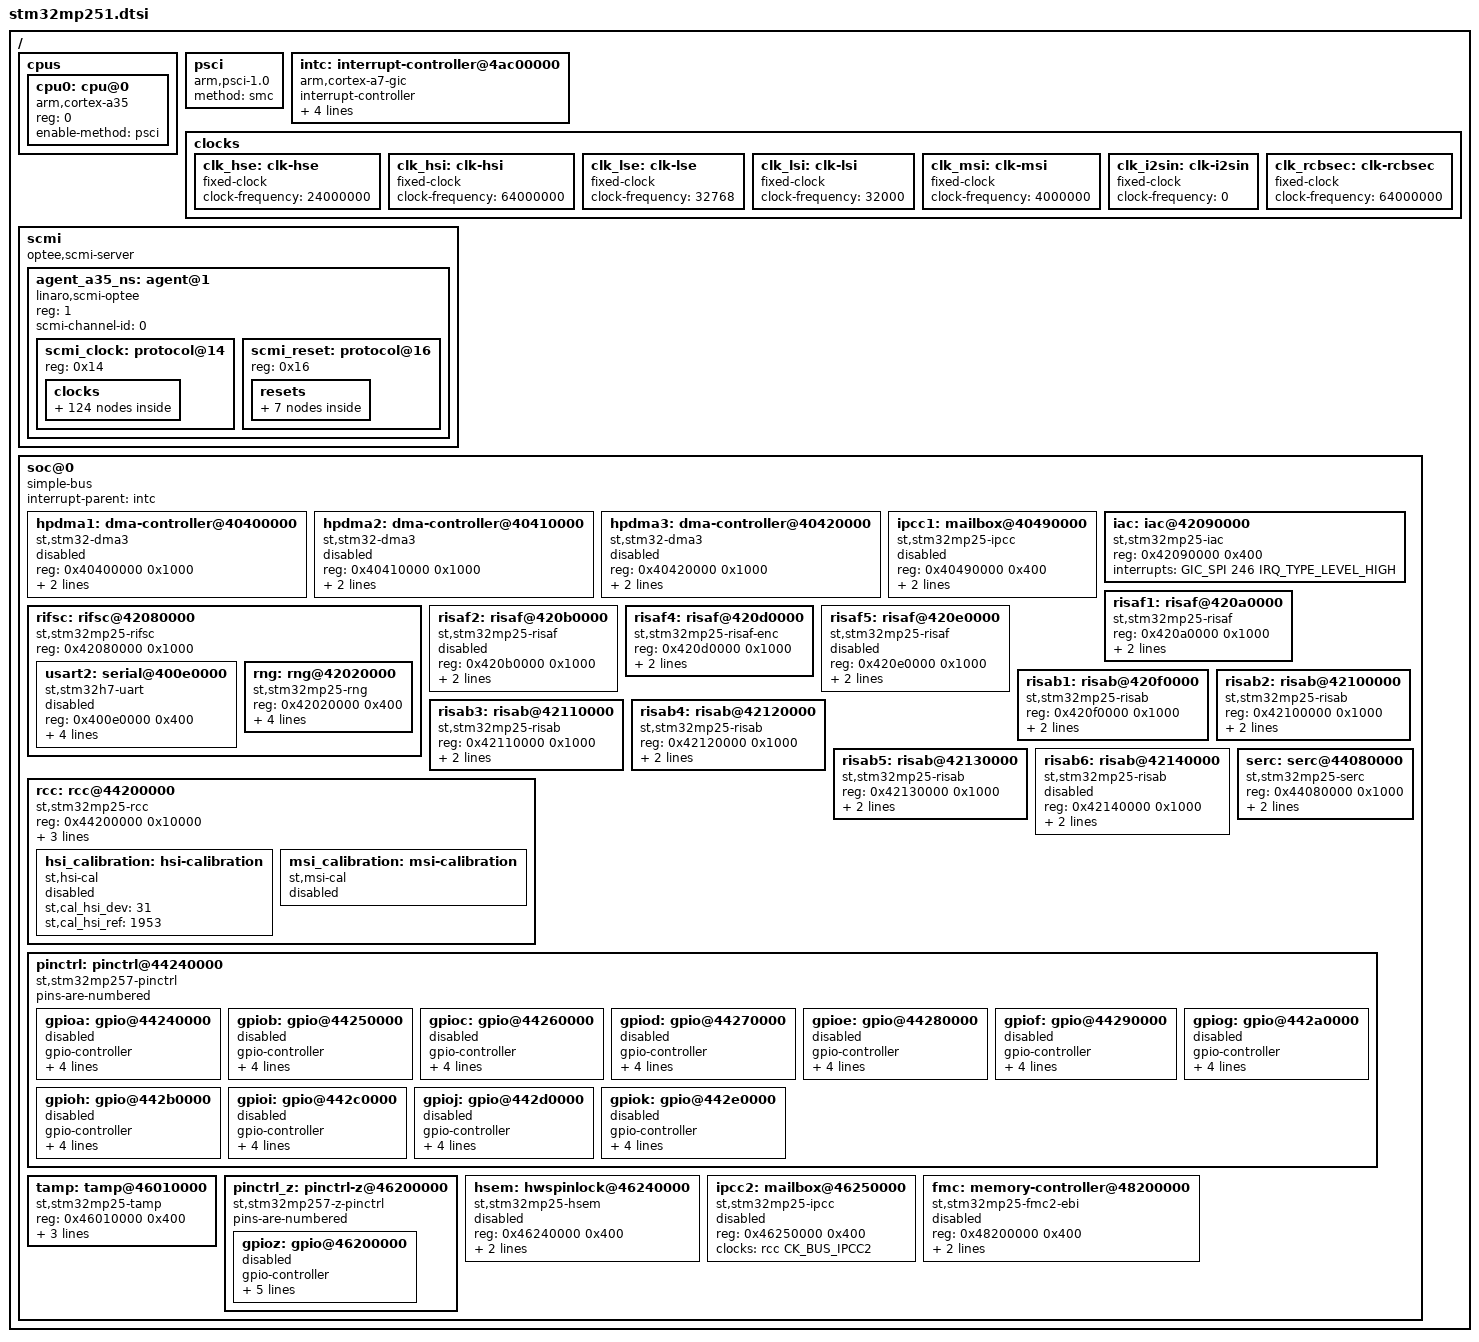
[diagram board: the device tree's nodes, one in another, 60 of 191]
// SPDX-License-Identifier: (GPL-2.0-or-later OR BSD-3-Clause)
/*
 * Copyright (C) STMicroelectronics 2023 - All Rights Reserved
 * Author: Alexandre Torgue <alexandre.torgue@foss.st.com> for STMicroelectronics.
 */

#include <dt-bindings/clock/st,stm32mp25-rcc.h>
#include <dt-bindings/firewall/stm32mp25-rif.h>
#include <dt-bindings/firewall/stm32mp25-rifsc.h>
#include <dt-bindings/firewall/stm32mp25-risaf.h>
#include <dt-bindings/firewall/stm32mp25-risab.h>
#include <dt-bindings/interrupt-controller/arm-gic.h>
#include <dt-bindings/reset/st,stm32mp25-rcc.h>
#include <dt-bindings/scmi/scmi-clock.h>

/ {
	#address-cells = <2>;
	#size-cells = <2>;

	cpus {
		#address-cells = <1>;
		#size-cells = <0>;

		cpu0: cpu@0 {
			compatible = "arm,cortex-a35";
			device_type = "cpu";
			reg = <0>;
			enable-method = "psci";
		};
	};

	psci {
		compatible = "arm,psci-1.0";
		method = "smc";
	};

	intc: interrupt-controller@4ac00000 {
		compatible = "arm,cortex-a7-gic";
		#interrupt-cells = <3>;
		interrupt-controller;
		reg = <0x0 0x4ac10000 0x0 0x1000>,
		      <0x0 0x4ac20000 0x0 0x2000>,
		      <0x0 0x4ac40000 0x0 0x2000>,
		      <0x0 0x4ac60000 0x0 0x2000>;
		#address-cells = <1>;
	};

	clocks {
		clk_hse: clk-hse {
			#clock-cells = <0>;
			compatible = "fixed-clock";
			clock-frequency = <24000000>;
		};

		clk_hsi: clk-hsi {
			#clock-cells = <0>;
			compatible = "fixed-clock";
			clock-frequency = <64000000>;
		};

		clk_lse: clk-lse {
			#clock-cells = <0>;
			compatible = "fixed-clock";
			clock-frequency = <32768>;
		};

		clk_lsi: clk-lsi {
			#clock-cells = <0>;
			compatible = "fixed-clock";
			clock-frequency = <32000>;
		};

		clk_msi: clk-msi {
			#clock-cells = <0>;
			compatible = "fixed-clock";
			clock-frequency = <4000000>;
		};

		clk_i2sin: clk-i2sin {
			#clock-cells = <0>;
			compatible = "fixed-clock";
			clock-frequency = <0>;
		};

		clk_rcbsec: clk-rcbsec {
			#clock-cells = <0>;
			compatible = "fixed-clock";
			clock-frequency = <64000000>;
		};
	};

	scmi: scmi {
		compatible = "optee,scmi-server";
		#address-cells = <1>;
		#size-cells = <0>;

		agent_a35_ns: agent@1 {
			reg = <1>;
			compatible = "linaro,scmi-optee";
			scmi-channel-id = <0>;
			#address-cells = <1>;
			#size-cells = <0>;

			scmi_clock: protocol@14 {
				reg = <0x14>;

				clocks {
					#address-cells = <1>;
					#size-cells = <0>;

					clock@0 {
						reg = <CK_SCMI_ICN_HS_MCU>;
						domain-name = "ck_icn_hs_mcu";
						clocks = <&rcc CK_ICN_HS_MCU>;
						flags = <SCMI_CLOCK_DEFAULT_ENABLED>;
					};

					clock@1 {
						reg = <CK_SCMI_ICN_SDMMC>;
						domain-name = "ck_icn_sdmmc";
						clocks = <&rcc CK_ICN_SDMMC>;
						flags = <SCMI_CLOCK_DEFAULT_ENABLED>;
					};

					clock@2 {
						reg = <CK_SCMI_ICN_DDR>;
						domain-name = "ck_icn_ddr";
						clocks = <&rcc CK_ICN_DDR>;
						flags = <SCMI_CLOCK_DEFAULT_ENABLED>;
					};

					clock@3 {
						reg = <CK_SCMI_ICN_DISPLAY>;
						domain-name = "ck_icn_display";
						clocks = <&rcc CK_ICN_DISPLAY>;
						flags = <SCMI_CLOCK_DEFAULT_ENABLED>;
					};

					clock@4 {
						reg = <CK_SCMI_ICN_HSL>;
						domain-name = "ck_icn_hsl";
						clocks = <&rcc CK_ICN_HSL>;
						flags = <SCMI_CLOCK_DEFAULT_ENABLED>;
					};

					clock@5 {
						reg = <CK_SCMI_ICN_NIC>;
						domain-name = "ck_icn_nic";
						clocks = <&rcc CK_ICN_NIC>;
						flags = <SCMI_CLOCK_DEFAULT_ENABLED>;
					};

					clock@6 {
						reg = <CK_SCMI_ICN_VID>;
						domain-name = "ck_icn_vid";
						clocks = <&rcc CK_ICN_VID>;
						flags = <SCMI_CLOCK_DEFAULT_ENABLED>;
					};

					clock@7 {
						reg = <CK_SCMI_FLEXGEN_07>;
						domain-name = "ck_flexgen_07";
						clocks = <&rcc CK_FLEXGEN_07>;
						flags = <SCMI_CLOCK_DEFAULT_ENABLED>;
					};

					clock@8 {
						reg = <CK_SCMI_FLEXGEN_08>;
						domain-name = "ck_flexgen_08";
						clocks = <&rcc CK_FLEXGEN_08>;
						flags = <SCMI_CLOCK_DEFAULT_ENABLED>;
					};

					clock@9 {
						reg = <CK_SCMI_FLEXGEN_09>;
						domain-name = "ck_flexgen_09";
						clocks = <&rcc CK_FLEXGEN_09>;
						flags = <SCMI_CLOCK_DEFAULT_ENABLED>;
					};

					clock@a {
						reg = <CK_SCMI_FLEXGEN_10>;
						domain-name = "ck_flexgen_10";
						clocks = <&rcc CK_FLEXGEN_10>;
						flags = <(SCMI_CLOCK_DEFAULT_ENABLED |
							  SCMI_CLOCK_ALLOW_SET_RATE)>;
					};

					clock@b {
						reg = <CK_SCMI_FLEXGEN_11>;
						domain-name = "ck_flexgen_11";
						clocks = <&rcc CK_FLEXGEN_11>;
						flags = <SCMI_CLOCK_DEFAULT_ENABLED>;
					};

					clock@c {
						reg = <CK_SCMI_FLEXGEN_12>;
						domain-name = "ck_flexgen_12";
						clocks = <&rcc CK_FLEXGEN_12>;
						flags = <SCMI_CLOCK_DEFAULT_ENABLED>;
					};

					clock@d {
						reg = <CK_SCMI_FLEXGEN_13>;
						domain-name = "ck_flexgen_13";
						clocks = <&rcc CK_FLEXGEN_13>;
						flags = <SCMI_CLOCK_DEFAULT_ENABLED>;
					};

					clock@e {
						reg = <CK_SCMI_FLEXGEN_14>;
						domain-name = "ck_flexgen_14";
						clocks = <&rcc CK_FLEXGEN_14>;
						flags = <SCMI_CLOCK_DEFAULT_ENABLED>;
					};

					clock@f {
						reg = <CK_SCMI_FLEXGEN_15>;
						domain-name = "ck_flexgen_15";
						clocks = <&rcc CK_FLEXGEN_15>;
						flags = <SCMI_CLOCK_DEFAULT_ENABLED>;
					};

					clock@10 {
						reg = <CK_SCMI_FLEXGEN_16>;
						domain-name = "ck_flexgen_16";
						clocks = <&rcc CK_FLEXGEN_16>;
						flags = <(SCMI_CLOCK_DEFAULT_ENABLED |
							  SCMI_CLOCK_ALLOW_SET_RATE)>;
					};

					clock@11 {
						reg = <CK_SCMI_FLEXGEN_17>;
						domain-name = "ck_flexgen_17";
						clocks = <&rcc CK_FLEXGEN_17>;
						flags = <SCMI_CLOCK_DEFAULT_ENABLED>;
					};

					clock@12 {
						reg = <CK_SCMI_FLEXGEN_18>;
						domain-name = "ck_flexgen_18";
						clocks = <&rcc CK_FLEXGEN_18>;
						flags = <SCMI_CLOCK_DEFAULT_ENABLED>;
					};

					clock@13 {
						reg = <CK_SCMI_FLEXGEN_19>;
						domain-name = "ck_flexgen_19";
						clocks = <&rcc CK_FLEXGEN_19>;
						flags = <SCMI_CLOCK_DEFAULT_ENABLED>;
					};

					clock@14 {
						reg = <CK_SCMI_FLEXGEN_20>;
						domain-name = "ck_flexgen_20";
						clocks = <&rcc CK_FLEXGEN_20>;
						flags = <SCMI_CLOCK_DEFAULT_ENABLED>;
					};

					clock@15 {
						reg = <CK_SCMI_FLEXGEN_21>;
						domain-name = "ck_flexgen_21";
						clocks = <&rcc CK_FLEXGEN_21>;
						flags = <SCMI_CLOCK_DEFAULT_ENABLED>;
					};

					clock@16 {
						reg = <CK_SCMI_FLEXGEN_22>;
						domain-name = "ck_flexgen_22";
						clocks = <&rcc CK_FLEXGEN_22>;
						flags = <SCMI_CLOCK_DEFAULT_ENABLED>;
					};

					clock@17 {
						reg = <CK_SCMI_FLEXGEN_23>;
						domain-name = "ck_flexgen_23";
						clocks = <&rcc CK_FLEXGEN_23>;
						flags = <(SCMI_CLOCK_DEFAULT_ENABLED |
							  SCMI_CLOCK_ALLOW_SET_RATE)>;
					};

					clock@18 {
						reg = <CK_SCMI_FLEXGEN_24>;
						domain-name = "ck_flexgen_24";
						clocks = <&rcc CK_FLEXGEN_24>;
						flags = <(SCMI_CLOCK_DEFAULT_ENABLED |
							  SCMI_CLOCK_ALLOW_SET_RATE)>;
					};

					clock@19 {
						reg = <CK_SCMI_FLEXGEN_25>;
						domain-name = "ck_flexgen_25";
						clocks = <&rcc CK_FLEXGEN_25>;
						flags = <(SCMI_CLOCK_DEFAULT_ENABLED |
							  SCMI_CLOCK_ALLOW_SET_RATE)>;
					};

					clock@1a {
						reg = <CK_SCMI_FLEXGEN_26>;
						domain-name = "ck_flexgen_26";
						clocks = <&rcc CK_FLEXGEN_26>;
						flags = <SCMI_CLOCK_DEFAULT_ENABLED>;
					};

					clock@1b {
						reg = <CK_SCMI_FLEXGEN_27>;
						domain-name = "ck_flexgen_27";
						clocks = <&rcc CK_FLEXGEN_27>;
						flags = <(SCMI_CLOCK_DEFAULT_ENABLED |
							  SCMI_CLOCK_ALLOW_SET_RATE)>;
					};

					clock@1c {
						reg = <CK_SCMI_FLEXGEN_28>;
						domain-name = "ck_flexgen_28";
						clocks = <&rcc CK_FLEXGEN_28>;
						flags = <SCMI_CLOCK_DEFAULT_ENABLED>;
					};

					clock@1d {
						reg = <CK_SCMI_FLEXGEN_29>;
						domain-name = "ck_flexgen_29";
						clocks = <&rcc CK_FLEXGEN_29>;
						flags = <SCMI_CLOCK_DEFAULT_ENABLED>;
					};

					clock@1e {
						reg = <CK_SCMI_FLEXGEN_30>;
						domain-name = "ck_flexgen_30";
						clocks = <&rcc CK_FLEXGEN_30>;
						flags = <SCMI_CLOCK_DEFAULT_ENABLED>;
					};

					clock@1f {
						reg = <CK_SCMI_FLEXGEN_31>;
						domain-name = "ck_flexgen_31";
						clocks = <&rcc CK_FLEXGEN_31>;
						flags = <SCMI_CLOCK_DEFAULT_ENABLED>;
					};

					clock@20 {
						reg = <CK_SCMI_FLEXGEN_32>;
						domain-name = "ck_flexgen_32";
						clocks = <&rcc CK_FLEXGEN_32>;
						flags = <SCMI_CLOCK_DEFAULT_ENABLED>;
					};

					clock@21 {
						reg = <CK_SCMI_FLEXGEN_33>;
						domain-name = "ck_flexgen_33";
						clocks = <&rcc CK_FLEXGEN_33>;
						flags = <SCMI_CLOCK_DEFAULT_ENABLED>;
					};

					clock@22 {
						reg = <CK_SCMI_FLEXGEN_34>;
						domain-name = "ck_flexgen_34";
						clocks = <&rcc CK_FLEXGEN_34>;
						flags = <SCMI_CLOCK_DEFAULT_ENABLED>;
					};

					clock@23 {
						reg = <CK_SCMI_FLEXGEN_35>;
						domain-name = "ck_flexgen_35";
						clocks = <&rcc CK_FLEXGEN_35>;
						flags = <SCMI_CLOCK_DEFAULT_ENABLED>;
					};

					clock@24 {
						reg = <CK_SCMI_FLEXGEN_36>;
						domain-name = "ck_flexgen_36";
						clocks = <&rcc CK_FLEXGEN_36>;
						flags = <SCMI_CLOCK_DEFAULT_ENABLED>;
					};

					clock@25 {
						reg = <CK_SCMI_FLEXGEN_37>;
						domain-name = "ck_flexgen_37";
						clocks = <&rcc CK_FLEXGEN_37>;
						flags = <SCMI_CLOCK_DEFAULT_ENABLED>;
					};

					clock@26 {
						reg = <CK_SCMI_FLEXGEN_38>;
						domain-name = "ck_flexgen_38";
						clocks = <&rcc CK_FLEXGEN_38>;
						flags = <SCMI_CLOCK_DEFAULT_ENABLED>;
					};

					clock@27 {
						reg = <CK_SCMI_FLEXGEN_39>;
						domain-name = "ck_flexgen_39";
						clocks = <&rcc CK_FLEXGEN_39>;
						flags = <SCMI_CLOCK_DEFAULT_ENABLED>;
					};

					clock@28 {
						reg = <CK_SCMI_FLEXGEN_40>;
						domain-name = "ck_flexgen_40";
						clocks = <&rcc CK_FLEXGEN_40>;
						flags = <SCMI_CLOCK_DEFAULT_ENABLED>;
					};

					clock@29 {
						reg = <CK_SCMI_FLEXGEN_41>;
						domain-name = "ck_flexgen_41";
						clocks = <&rcc CK_FLEXGEN_41>;
						flags = <SCMI_CLOCK_DEFAULT_ENABLED>;
					};

					clock@2a {
						reg = <CK_SCMI_FLEXGEN_42>;
						domain-name = "ck_flexgen_42";
						clocks = <&rcc CK_FLEXGEN_42>;
						flags = <SCMI_CLOCK_DEFAULT_ENABLED>;
					};

					clock@2b {
						reg = <CK_SCMI_FLEXGEN_43>;
						domain-name = "ck_flexgen_43";
						clocks = <&rcc CK_FLEXGEN_43>;
						flags = <SCMI_CLOCK_DEFAULT_ENABLED>;
					};

					clock@2c {
						reg = <CK_SCMI_FLEXGEN_44>;
						domain-name = "ck_flexgen_44";
						clocks = <&rcc CK_FLEXGEN_44>;
						flags = <SCMI_CLOCK_DEFAULT_ENABLED>;
					};

					clock@2d {
						reg = <CK_SCMI_FLEXGEN_45>;
						domain-name = "ck_flexgen_45";
						clocks = <&rcc CK_FLEXGEN_45>;
						flags = <SCMI_CLOCK_DEFAULT_ENABLED>;
					};

					clock@2e {
						reg = <CK_SCMI_FLEXGEN_46>;
						domain-name = "ck_flexgen_46";
						clocks = <&rcc CK_FLEXGEN_46>;
						flags = <SCMI_CLOCK_DEFAULT_ENABLED>;
					};

					clock@2f {
						reg = <CK_SCMI_FLEXGEN_47>;
						domain-name = "ck_flexgen_47";
						clocks = <&rcc CK_FLEXGEN_47>;
						flags = <SCMI_CLOCK_DEFAULT_ENABLED>;
					};

					clock@30 {
						reg = <CK_SCMI_FLEXGEN_48>;
						domain-name = "ck_flexgen_48";
						clocks = <&rcc CK_FLEXGEN_48>;
						flags = <SCMI_CLOCK_DEFAULT_ENABLED>;
					};

					clock@31 {
						reg = <CK_SCMI_FLEXGEN_49>;
						domain-name = "ck_flexgen_49";
						clocks = <&rcc CK_FLEXGEN_49>;
						flags = <SCMI_CLOCK_DEFAULT_ENABLED>;
					};

					clock@32 {
						reg = <CK_SCMI_FLEXGEN_50>;
						domain-name = "ck_flexgen_50";
						clocks = <&rcc CK_FLEXGEN_50>;
						flags = <SCMI_CLOCK_DEFAULT_ENABLED>;
					};

					clock@33 {
						reg = <CK_SCMI_FLEXGEN_51>;
						domain-name = "ck_flexgen_51";
						clocks = <&rcc CK_FLEXGEN_51>;
						flags = <SCMI_CLOCK_DEFAULT_ENABLED>;
					};

					clock@34 {
						reg = <CK_SCMI_FLEXGEN_52>;
						domain-name = "ck_flexgen_52";
						clocks = <&rcc CK_FLEXGEN_52>;
						flags = <SCMI_CLOCK_DEFAULT_ENABLED>;
					};

					clock@35 {
						reg = <CK_SCMI_FLEXGEN_53>;
						domain-name = "ck_flexgen_53";
						clocks = <&rcc CK_FLEXGEN_53>;
						flags = <SCMI_CLOCK_DEFAULT_ENABLED>;
					};

					clock@36 {
						reg = <CK_SCMI_FLEXGEN_54>;
						domain-name = "ck_flexgen_54";
						clocks = <&rcc CK_FLEXGEN_54>;
						flags = <SCMI_CLOCK_DEFAULT_ENABLED>;
					};

					clock@37 {
						reg = <CK_SCMI_FLEXGEN_55>;
						domain-name = "ck_flexgen_55";
						clocks = <&rcc CK_FLEXGEN_55>;
						flags = <SCMI_CLOCK_DEFAULT_ENABLED>;
					};

					clock@38 {
						reg = <CK_SCMI_FLEXGEN_56>;
						domain-name = "ck_flexgen_56";
						clocks = <&rcc CK_FLEXGEN_56>;
						flags = <SCMI_CLOCK_DEFAULT_ENABLED>;
					};

					clock@39 {
						reg = <CK_SCMI_FLEXGEN_57>;
						domain-name = "ck_flexgen_57";
						clocks = <&rcc CK_FLEXGEN_57>;
						flags = <SCMI_CLOCK_DEFAULT_ENABLED>;
					};

					clock@3a {
						reg = <CK_SCMI_FLEXGEN_58>;
						domain-name = "ck_flexgen_58";
						clocks = <&rcc CK_FLEXGEN_58>;
						flags = <SCMI_CLOCK_DEFAULT_ENABLED>;
					};

					clock@3b {
						reg = <CK_SCMI_FLEXGEN_59>;
						domain-name = "ck_flexgen_59";
						clocks = <&rcc CK_FLEXGEN_59>;
						flags = <SCMI_CLOCK_DEFAULT_ENABLED>;
					};

					clock@3c {
						reg = <CK_SCMI_FLEXGEN_60>;
						domain-name = "ck_flexgen_60";
						clocks = <&rcc CK_FLEXGEN_60>;
						flags = <SCMI_CLOCK_DEFAULT_ENABLED>;
					};

					clock@3d {
						reg = <CK_SCMI_FLEXGEN_61>;
						domain-name = "ck_flexgen_61";
						clocks = <&rcc CK_FLEXGEN_61>;
						flags = <SCMI_CLOCK_DEFAULT_ENABLED>;
					};

					clock@3e {
						reg = <CK_SCMI_FLEXGEN_62>;
						domain-name = "ck_flexgen_62";
						clocks = <&rcc CK_FLEXGEN_62>;
						flags = <SCMI_CLOCK_DEFAULT_ENABLED>;
					};

					clock@3f {
						reg = <CK_SCMI_FLEXGEN_63>;
						domain-name = "ck_flexgen_63";
						clocks = <&rcc CK_FLEXGEN_63>;
						flags = <SCMI_CLOCK_DEFAULT_ENABLED>;
					};

					clock@40 {
						reg = <CK_SCMI_ICN_LS_MCU>;
						domain-name = "ck_icn_ls_mcu";
						clocks = <&rcc CK_ICN_LS_MCU>;
						flags = <SCMI_CLOCK_DEFAULT_ENABLED>;
					};

					clock@41 {
						reg = <CK_SCMI_HSE>;
						domain-name = "hse_ck";
						clocks = <&rcc HSE_CK>;
						flags = <SCMI_CLOCK_DEFAULT_ENABLED>;
					};

					clock@42 {
						reg = <CK_SCMI_LSE>;
						domain-name = "lse_ck";
						clocks = <&rcc LSE_CK>;
						flags = <SCMI_CLOCK_DEFAULT_ENABLED>;
					};

					clock@43 {
						reg = <CK_SCMI_HSI>;
						domain-name = "hsi_ck";
						clocks = <&rcc HSI_CK>;
						flags = <SCMI_CLOCK_DEFAULT_ENABLED>;
					};

					clock@44 {
						reg = <CK_SCMI_LSI>;
						domain-name = "lsi_ck";
						clocks = <&rcc LSI_CK>;
						flags = <SCMI_CLOCK_DEFAULT_ENABLED>;
					};

					clock@45 {
						reg = <CK_SCMI_MSI>;
						domain-name = "msi_ck";
						clocks = <&rcc MSI_CK>;
						flags = <SCMI_CLOCK_DEFAULT_ENABLED>;
					};

					clock@46 {
						reg = <CK_SCMI_HSE_DIV2>;
						domain-name = "hse_div2_ck";
						clocks = <&rcc HSE_DIV2_CK>;
					};

					clock@47 {
						reg = <CK_SCMI_CPU1>;
						domain-name = "ck_cpu1";
						clocks = <&rcc CK_CPU1>;
						flags = <SCMI_CLOCK_DEFAULT_ENABLED>;
					};

					clock@48 {
						reg = <CK_SCMI_SYSCPU1>;
						domain-name = "ck_bus_syscpu1";
						clocks = <&rcc CK_BUS_SYSCPU1>;
						flags = <SCMI_CLOCK_DEFAULT_ENABLED>;
					};

					clock@49 {
						reg = <CK_SCMI_PLL2>;
						domain-name = "ck_pll2";
						clocks = <&rcc PLL2_CK>;
						flags = <SCMI_CLOCK_DEFAULT_ENABLED>;
					};

					clock@4a {
						reg = <CK_SCMI_PLL3>;
						domain-name = "ck_pll3";
						clocks = <&rcc PLL3_CK>;
					};

					clock@4b {
						reg = <CK_SCMI_RTC>;
						domain-name = "ck_bus_rtc";
						clocks = <&rcc CK_BUS_RTC>;
						flags = <SCMI_CLOCK_DEFAULT_ENABLED>;
					};

					clock@4c {
						reg = <CK_SCMI_RTCCK>;
						domain-name = "rtc_ck";
						clocks = <&rcc RTC_CK>;
						flags = <SCMI_CLOCK_DEFAULT_ENABLED>;
					};

					clock@4d {
						reg = <CK_SCMI_ICN_APB1>;
						domain-name = "ck_icn_apb1";
						clocks = <&rcc CK_ICN_APB1>;
						flags = <SCMI_CLOCK_DEFAULT_ENABLED>;
					};

					clock@4e {
						reg = <CK_SCMI_ICN_APB2>;
						domain-name = "ck_icn_apb2";
						clocks = <&rcc CK_ICN_APB2>;
						flags = <SCMI_CLOCK_DEFAULT_ENABLED>;
					};

					clock@4f {
						reg = <CK_SCMI_ICN_APB3>;
						domain-name = "ck_icn_apb3";
						clocks = <&rcc CK_ICN_APB3>;
						flags = <SCMI_CLOCK_DEFAULT_ENABLED>;
					};

					clock@50 {
						reg = <CK_SCMI_ICN_APB4>;
						domain-name = "ck_icn_apb4";
						clocks = <&rcc CK_ICN_APB4>;
						flags = <SCMI_CLOCK_DEFAULT_ENABLED>;
					};

					clock@51 {
						reg = <CK_SCMI_ICN_APBDBG>;
						domain-name = "ck_icn_apbdbg";
						clocks = <&rcc CK_ICN_APBDBG>;
						flags = <SCMI_CLOCK_DEFAULT_ENABLED>;
					};

					clock@52 {
						reg = <CK_SCMI_TIMG1>;
						domain-name = "timg1_ck";
						clocks = <&rcc TIMG1_CK>;
						flags = <SCMI_CLOCK_DEFAULT_ENABLED>;
					};

					clock@53 {
						reg = <CK_SCMI_TIMG2>;
						domain-name = "timg2_ck";
						clocks = <&rcc TIMG2_CK>;
						flags = <SCMI_CLOCK_DEFAULT_ENABLED>;
					};

					clock@54 {
						reg = <CK_SCMI_BKPSRAM>;
						domain-name = "ck_bus_bkpsram";
						clocks = <&rcc CK_BUS_BKPSRAM>;
						flags = <SCMI_CLOCK_DEFAULT_ENABLED>;
					};

					clock@55 {
						reg = <CK_SCMI_BSEC>;
						domain-name = "ck_bus_bsec";
						clocks = <&rcc CK_BUS_BSEC>;
						flags = <SCMI_CLOCK_DEFAULT_ENABLED>;
					};

					clock@57 {
						reg = <CK_SCMI_BUS_ETR>;
						domain-name = "ck_icn_p_etr";
						clocks = <&rcc CK_BUS_ETR>;
						flags = <SCMI_CLOCK_DEFAULT_ENABLED>;
					};

					clock@58 {
						reg = <CK_SCMI_FMC>;
						domain-name = "ck_ker_fmc";
						clocks = <&rcc CK_KER_FMC>;
						flags = <SCMI_CLOCK_DEFAULT_ENABLED>;
					};

					clock@59 {
						reg = <CK_SCMI_GPIOA>;
						domain-name = "ck_bus_gpioa";
						clocks = <&rcc CK_BUS_GPIOA>;
						flags = <SCMI_CLOCK_DEFAULT_ENABLED>;
					};

					clock@5a {
						reg = <CK_SCMI_GPIOB>;
						domain-name = "ck_bus_gpiob";
						clocks = <&rcc CK_BUS_GPIOB>;
						flags = <SCMI_CLOCK_DEFAULT_ENABLED>;
					};

					clock@5b {
						reg = <CK_SCMI_GPIOC>;
						domain-name = "ck_bus_gpioc";
						clocks = <&rcc CK_BUS_GPIOC>;
						flags = <SCMI_CLOCK_DEFAULT_ENABLED>;
					};

					clock@5c {
						reg = <CK_SCMI_GPIOD>;
						domain-name = "ck_bus_gpiod";
						clocks = <&rcc CK_BUS_GPIOD>;
						flags = <SCMI_CLOCK_DEFAULT_ENABLED>;
					};

					clock@5d {
						reg = <CK_SCMI_GPIOE>;
						domain-name = "ck_bus_gpioe";
						clocks = <&rcc CK_BUS_GPIOE>;
						flags = <SCMI_CLOCK_DEFAULT_ENABLED>;
					};

					clock@5e {
						reg = <CK_SCMI_GPIOF>;
						domain-name = "ck_bus_gpiof";
						clocks = <&rcc CK_BUS_GPIOF>;
						flags = <SCMI_CLOCK_DEFAULT_ENABLED>;
					};

					clock@5f {
						reg = <CK_SCMI_GPIOG>;
						domain-name = "ck_bus_gpiog";
						clocks = <&rcc CK_BUS_GPIOG>;
						flags = <SCMI_CLOCK_DEFAULT_ENABLED>;
					};

					clock@60 {
						reg = <CK_SCMI_GPIOH>;
						domain-name = "ck_bus_gpioh";
						clocks = <&rcc CK_BUS_GPIOH>;
						flags = <SCMI_CLOCK_DEFAULT_ENABLED>;
					};

					clock@61 {
						reg = <CK_SCMI_GPIOI>;
						domain-name = "ck_bus_gpioi";
						clocks = <&rcc CK_BUS_GPIOI>;
						flags = <SCMI_CLOCK_DEFAULT_ENABLED>;
					};

					clock@62 {
						reg = <CK_SCMI_GPIOJ>;
						domain-name = "ck_bus_gpioj";
						clocks = <&rcc CK_BUS_GPIOJ>;
						flags = <SCMI_CLOCK_DEFAULT_ENABLED>;
					};

					clock@63 {
						reg = <CK_SCMI_GPIOK>;
						domain-name = "ck_bus_gpiok";
						clocks = <&rcc CK_BUS_GPIOK>;
						flags = <SCMI_CLOCK_DEFAULT_ENABLED>;
					};

					clock@64 {
						reg = <CK_SCMI_GPIOZ>;
						domain-name = "ck_bus_gpioz";
						clocks = <&rcc CK_BUS_GPIOZ>;
						flags = <SCMI_CLOCK_DEFAULT_ENABLED>;
					};

					clock@65 {
						reg = <CK_SCMI_HPDMA1>;
						domain-name = "ck_bus_hpdma1";
						clocks = <&rcc CK_BUS_HPDMA1>;
						flags = <SCMI_CLOCK_DEFAULT_ENABLED>;
					};

					clock@66 {
						reg = <CK_SCMI_HPDMA2>;
						domain-name = "ck_bus_hpdma2";
						clocks = <&rcc CK_BUS_HPDMA2>;
						flags = <SCMI_CLOCK_DEFAULT_ENABLED>;
					};

					clock@67 {
						reg = <CK_SCMI_HPDMA3>;
						domain-name = "ck_bus_hpdma3";
						clocks = <&rcc CK_BUS_HPDMA3>;
						flags = <SCMI_CLOCK_DEFAULT_ENABLED>;
					};

					clock@68 {
						reg = <CK_SCMI_HSEM>;
						domain-name = "ck_bus_hsem";
						clocks = <&rcc CK_BUS_HSEM>;
						flags = <SCMI_CLOCK_DEFAULT_ENABLED>;
					};

					clock@69 {
						reg = <CK_SCMI_IPCC1>;
						domain-name = "ck_bus_ipcc1";
						clocks = <&rcc CK_BUS_IPCC1>;
						flags = <SCMI_CLOCK_DEFAULT_ENABLED>;
					};

					clock@6a {
						reg = <CK_SCMI_IPCC2>;
						domain-name = "ck_bus_ipcc2";
						clocks = <&rcc CK_BUS_IPCC2>;
						flags = <SCMI_CLOCK_DEFAULT_ENABLED>;
					};

					clock@6b {
						reg = <CK_SCMI_LPDMA>;
						domain-name = "ck_bus_lpdma";
						clocks = <&rcc CK_BUS_LPDMA>;
						flags = <SCMI_CLOCK_DEFAULT_ENABLED>;
					};

					clock@6c {
						reg = <CK_SCMI_RETRAM>;
						domain-name = "ck_bus_retram";
						clocks = <&rcc CK_BUS_RETRAM>;
						flags = <SCMI_CLOCK_DEFAULT_ENABLED>;
					};

					clock@6d {
						reg = <CK_SCMI_SRAM1>;
						domain-name = "ck_bus_sram1";
						clocks = <&rcc CK_BUS_SRAM1>;
						flags = <SCMI_CLOCK_DEFAULT_ENABLED>;
					};

					clock@6e {
						reg = <CK_SCMI_SRAM2>;
						domain-name = "ck_bus_sram2";
						clocks = <&rcc CK_BUS_SRAM2>;
						flags = <SCMI_CLOCK_DEFAULT_ENABLED>;
					};

					clock@6f {
						reg = <CK_SCMI_LPSRAM1>;
						domain-name = "ck_icn_lpsram1";
						clocks = <&rcc CK_BUS_LPSRAM1>;
						flags = <SCMI_CLOCK_DEFAULT_ENABLED>;
					};

					clock@70 {
						reg = <CK_SCMI_LPSRAM2>;
						domain-name = "ck_icn_lpsram2";
						clocks = <&rcc CK_BUS_LPSRAM2>;
						flags = <SCMI_CLOCK_DEFAULT_ENABLED>;
					};

					clock@71 {
						reg = <CK_SCMI_LPSRAM3>;
						domain-name = "ck_icn_lpsram3";
						clocks = <&rcc CK_BUS_LPSRAM3>;
						flags = <SCMI_CLOCK_DEFAULT_ENABLED>;
					};

					clock@72 {
						reg = <CK_SCMI_VDERAM>;
						domain-name = "ck_icn_s_vderam";
						clocks = <&rcc CK_BUS_VDERAM>;
						flags = <SCMI_CLOCK_DEFAULT_ENABLED>;
					};

					clock@73 {
						reg = <CK_SCMI_SYSRAM>;
						domain-name = "ck_icn_s_sysram";
						clocks = <&rcc CK_BUS_SYSRAM>;
						flags = <SCMI_CLOCK_DEFAULT_ENABLED>;
					};

					clock@74 {
						reg = <CK_SCMI_OSPI1>;
						domain-name = "ck_ker_ospi1";
						clocks = <&rcc CK_KER_OSPI1>;
						flags = <SCMI_CLOCK_DEFAULT_ENABLED>;
					};

					clock@75 {
						reg = <CK_SCMI_OSPI2>;
						domain-name = "ck_ker_ospi2";
						clocks = <&rcc CK_KER_OSPI2>;
						flags = <SCMI_CLOCK_DEFAULT_ENABLED>;
					};

					clock@76 {
						reg = <CK_SCMI_TPIU>;
						domain-name = "ck_ker_tpiu";
						clocks = <&rcc CK_KER_TPIU>;
						flags = <SCMI_CLOCK_DEFAULT_ENABLED>;
					};

					clock@77 {
						reg = <CK_SCMI_SYSDBG>;
						domain-name = "ck_sys_dbg";
						clocks = <&rcc CK_SYSDBG>;
						flags = <SCMI_CLOCK_DEFAULT_ENABLED>;
					};

					clock@78 {
						reg = <CK_SCMI_SYSATB>;
						domain-name = "ck_sys_atb";
						clocks = <&rcc CK_BUS_SYSATB>;
						flags = <SCMI_CLOCK_DEFAULT_ENABLED>;
					};

					clock@79 {
						reg = <CK_SCMI_TSDBG>;
						domain-name = "ck_ker_tsdbg";
						clocks = <&rcc CK_KER_TSDBG>;
						flags = <SCMI_CLOCK_DEFAULT_ENABLED>;
					};

					clock@7a {
						reg = <CK_SCMI_BUS_STM>;
						domain-name = "ck_icn_p_stm";
						clocks = <&rcc CK_BUS_STM>;
						flags = <SCMI_CLOCK_DEFAULT_ENABLED>;
					};

					clock@7b {
						reg = <CK_SCMI_KER_STM>;
						domain-name = "ck_icn_s_stm";
						clocks = <&rcc CK_KER_STM>;
						flags = <SCMI_CLOCK_DEFAULT_ENABLED>;
					};

					clock@7c {
						reg = <CK_SCMI_KER_ETR>;
						domain-name = "ck_icn_m_etr";
						clocks = <&rcc CK_KER_ETR>;
						flags = <SCMI_CLOCK_DEFAULT_ENABLED>;
					};
				};
			};

			scmi_reset: protocol@16 {
				reg = <0x16>;

				resets {
					#address-cells = <1>;
					#size-cells = <0>;

					reset@0 {
						reg = <RST_SCMI_C1_R>;
						domain-name = "c1";
						resets = <&rcc C1_R>;
					};

					reset@2 {
						reg = <RST_SCMI_C1_HOLDBOOT_R>;
						domain-name = "c1_holdboot";
						resets = <&rcc C1_HOLDBOOT_R>;
					};

					reset@4 {
						reg = <RST_SCMI_FMC>;
						domain-name = "fmc";
						resets = <&rcc FMC_R>;
					};

					reset@5 {
						reg = <RST_SCMI_OSPI1>;
						domain-name = "ospi1";
						resets = <&rcc OSPI1_R>;
					};

					reset@6 {
						reg = <RST_SCMI_OSPI1DLL>;
						domain-name = "ospi1_ddl";
						resets = <&rcc OSPI1DLL_R>;
					};

					reset@7 {
						reg = <RST_SCMI_OSPI2>;
						domain-name = "ospi2";
						resets = <&rcc OSPI2_R>;
					};

					reset@8 {
						reg = <RST_SCMI_OSPI2DLL>;
						domain-name = "ospi2_ddl";
						resets = <&rcc OSPI2DLL_R>;
					};
				};
			};
		};
	};

	soc@0 {
		compatible = "simple-bus";
		#address-cells = <1>;
		#size-cells = <1>;
		interrupt-parent = <&intc>;
		ranges = <0x0 0x0 0x0 0x80000000>;

		hpdma1: dma-controller@40400000 {
			compatible = "st,stm32-dma3";
			reg = <0x40400000 0x1000>;
			clocks = <&rcc CK_BUS_HPDMA1>;
			resets = <&rcc HPDMA1_R>;
			#dma-cells = <4>;
			status = "disabled";
		};

		hpdma2: dma-controller@40410000 {
			compatible = "st,stm32-dma3";
			reg = <0x40410000 0x1000>;
			clocks = <&rcc CK_BUS_HPDMA2>;
			resets = <&rcc HPDMA2_R>;
			#dma-cells = <4>;
			status = "disabled";
		};

		hpdma3: dma-controller@40420000 {
			compatible = "st,stm32-dma3";
			reg = <0x40420000 0x1000>;
			clocks = <&rcc CK_BUS_HPDMA3>;
			resets = <&rcc HPDMA3_R>;
			#dma-cells = <4>;
			status = "disabled";
		};

		ipcc1: mailbox@40490000 {
			compatible = "st,stm32mp25-ipcc";
			reg = <0x40490000 0x400>;
			interrupts = <GIC_SPI 173 IRQ_TYPE_LEVEL_HIGH>;
			interrupt-names = "rx";
			clocks = <&rcc CK_BUS_IPCC1>;
			status = "disabled";
		};

		rifsc: rifsc@42080000 {
			compatible = "st,stm32mp25-rifsc", "simple-bus";
			reg = <0x42080000 0x1000>;
			#address-cells = <1>;
			#size-cells = <1>;
			#access-controller-cells = <1>;

			usart2: serial@400e0000 {
				compatible = "st,stm32h7-uart";
				reg = <0x400e0000 0x400>;
				interrupts = <GIC_SPI 115 IRQ_TYPE_LEVEL_HIGH>;
				clocks = <&rcc CK_KER_USART2>;
				access-controllers = <&rifsc STM32MP25_RIFSC_USART2_ID>;
				status = "disabled";
			};

			rng: rng@42020000 {
				compatible = "st,stm32mp25-rng";
				reg = <0x42020000 0x400>;
				clocks = <&clk_rcbsec>, <&rcc CK_BUS_RNG>;
				clock-names = "rng_clk", "rng_hclk";
				resets = <&rcc RNG_R>;
				access-controllers = <&rifsc STM32MP25_RIFSC_RNG_ID>;
			};
		};

		iac: iac@42090000 {
			compatible = "st,stm32mp25-iac";
			reg = <0x42090000 0x400>;
			interrupts = <GIC_SPI 246 IRQ_TYPE_LEVEL_HIGH>;
		};

		risaf1: risaf@420a0000 {
			compatible = "st,stm32mp25-risaf";
			reg = <0x420a0000 0x1000>;
			clocks = <&rcc CK_BUS_BKPSRAM>;
			st,mem-map = <0x0 0x42000000 0x0 0x2000>;
		};

		risaf2: risaf@420b0000 {
			compatible = "st,stm32mp25-risaf";
			reg = <0x420b0000 0x1000>;
			clocks = <&rcc CK_KER_OSPI1>;
			st,mem-map = <0x0 0x60000000 0x0 0x10000000>;
			status = "disabled";
		};

		risaf4: risaf@420d0000 {
			compatible = "st,stm32mp25-risaf-enc";
			reg = <0x420d0000 0x1000>;
			clocks = <&rcc CK_BUS_RISAF4>;
			st,mem-map = <0x0 0x80000000 0x1 0x00000000>;
		};

		risaf5: risaf@420e0000 {
			compatible = "st,stm32mp25-risaf";
			reg = <0x420e0000 0x1000>;
			clocks = <&rcc CK_BUS_PCIE>;
			st,mem-map = <0x0 0x10000000 0x0 0x10000000>;
			status = "disabled";
		};

		risab1: risab@420f0000 {
			compatible = "st,stm32mp25-risab";
			reg = <0x420f0000 0x1000>;
			clocks = <&rcc CK_ICN_LS_MCU>;
			st,mem-map = <0xa000000 0x20000>;
			#access-controller-cells = <1>;
		};

		risab2: risab@42100000 {
			compatible = "st,stm32mp25-risab";
			reg = <0x42100000 0x1000>;
			clocks = <&rcc CK_ICN_LS_MCU>;
			st,mem-map = <0xa020000 0x20000>;
			#access-controller-cells = <1>;
		};

		risab3: risab@42110000 {
			compatible = "st,stm32mp25-risab";
			reg = <0x42110000 0x1000>;
			clocks = <&rcc CK_ICN_LS_MCU>;
			st,mem-map = <0xa040000 0x20000>;
			#access-controller-cells = <1>;
		};

		risab4: risab@42120000 {
			compatible = "st,stm32mp25-risab";
			reg = <0x42120000 0x1000>;
			clocks = <&rcc CK_ICN_LS_MCU>;
			st,mem-map = <0xa060000 0x20000>;
			#access-controller-cells = <1>;
		};

		risab5: risab@42130000 {
			compatible = "st,stm32mp25-risab";
			reg = <0x42130000 0x1000>;
			clocks = <&rcc CK_ICN_LS_MCU>;
			st,mem-map = <0xa080000 0x20000>;
			#access-controller-cells = <1>;
		};

		risab6: risab@42140000 {
			compatible = "st,stm32mp25-risab";
			reg = <0x42140000 0x1000>;
			clocks = <&rcc CK_ICN_LS_MCU>;
			st,mem-map = <0xa0a0000 0x20000>;
			#access-controller-cells = <1>;
			status = "disabled";
		};

		serc: serc@44080000 {
			compatible = "st,stm32mp25-serc";
			reg = <0x44080000 0x1000>;
			interrupts = <GIC_SPI 240 IRQ_TYPE_LEVEL_HIGH>;
			clocks = <&rcc CK_BUS_SERC>;
		};

		rcc: rcc@44200000 {
			compatible = "st,stm32mp25-rcc", "syscon";
			reg = <0x44200000 0x10000>;
			interrupts = <GIC_SPI 259 IRQ_TYPE_LEVEL_HIGH>;

			#clock-cells = <1>;
			#reset-cells = <1>;
			clocks = <&clk_hse>, <&clk_hsi>, <&clk_lse>,
				 <&clk_lsi>, <&clk_msi>, <&clk_i2sin>;
			clock-names = "clk-hse", "clk-hsi", "clk-lse",
				      "clk-lsi", "clk-msi", "clk-i2sin";

			hsi_calibration: hsi-calibration {
				compatible = "st,hsi-cal";
				st,cal_hsi_dev = <31>;
				st,cal_hsi_ref = <1953>;
				status = "disabled";
			};

			msi_calibration: msi-calibration {
				compatible = "st,msi-cal";
				status = "disabled";
			};
		};

		pinctrl: pinctrl@44240000 {
			#address-cells = <1>;
			#size-cells = <1>;
			compatible = "st,stm32mp257-pinctrl";
			ranges = <0 0x44240000 0xa0400>;
			pins-are-numbered;

			gpioa: gpio@44240000 {
				gpio-controller;
				#gpio-cells = <2>;
				interrupt-controller;
				#interrupt-cells = <2>;
				#access-controller-cells = <1>;
				reg = <0x0 0x400>;
				clocks = <&rcc CK_BUS_GPIOA>;
				st,bank-name = "GPIOA";
				status = "disabled";
			};

			gpiob: gpio@44250000 {
				gpio-controller;
				#gpio-cells = <2>;
				interrupt-controller;
				#interrupt-cells = <2>;
				#access-controller-cells = <1>;
				reg = <0x10000 0x400>;
				clocks = <&rcc CK_BUS_GPIOB>;
				st,bank-name = "GPIOB";
				status = "disabled";
			};

			gpioc: gpio@44260000 {
				gpio-controller;
				#gpio-cells = <2>;
				interrupt-controller;
				#interrupt-cells = <2>;
				#access-controller-cells = <1>;
				reg = <0x20000 0x400>;
				clocks = <&rcc CK_BUS_GPIOC>;
				st,bank-name = "GPIOC";
				status = "disabled";
			};

			gpiod: gpio@44270000 {
				gpio-controller;
				#gpio-cells = <2>;
				interrupt-controller;
				#interrupt-cells = <2>;
				#access-controller-cells = <1>;
				reg = <0x30000 0x400>;
				clocks = <&rcc CK_BUS_GPIOD>;
				st,bank-name = "GPIOD";
				status = "disabled";
			};

			gpioe: gpio@44280000 {
				gpio-controller;
				#gpio-cells = <2>;
				interrupt-controller;
				#interrupt-cells = <2>;
				#access-controller-cells = <1>;
				reg = <0x40000 0x400>;
				clocks = <&rcc CK_BUS_GPIOE>;
				st,bank-name = "GPIOE";
				status = "disabled";
			};

			gpiof: gpio@44290000 {
				gpio-controller;
				#gpio-cells = <2>;
				interrupt-controller;
				#interrupt-cells = <2>;
				#access-controller-cells = <1>;
				reg = <0x50000 0x400>;
				clocks = <&rcc CK_BUS_GPIOF>;
				st,bank-name = "GPIOF";
				status = "disabled";
			};

			gpiog: gpio@442a0000 {
				gpio-controller;
				#gpio-cells = <2>;
				interrupt-controller;
				#interrupt-cells = <2>;
				#access-controller-cells = <1>;
				reg = <0x60000 0x400>;
				clocks = <&rcc CK_BUS_GPIOG>;
				st,bank-name = "GPIOG";
				status = "disabled";
			};

			gpioh: gpio@442b0000 {
				gpio-controller;
				#gpio-cells = <2>;
				interrupt-controller;
				#interrupt-cells = <2>;
				#access-controller-cells = <1>;
				reg = <0x70000 0x400>;
				clocks = <&rcc CK_BUS_GPIOH>;
				st,bank-name = "GPIOH";
				status = "disabled";
			};

			gpioi: gpio@442c0000 {
				gpio-controller;
				#gpio-cells = <2>;
				interrupt-controller;
				#interrupt-cells = <2>;
				#access-controller-cells = <1>;
				reg = <0x80000 0x400>;
				clocks = <&rcc CK_BUS_GPIOI>;
				st,bank-name = "GPIOI";
				status = "disabled";
			};

			gpioj: gpio@442d0000 {
				gpio-controller;
				#gpio-cells = <2>;
				interrupt-controller;
				#interrupt-cells = <2>;
				#access-controller-cells = <1>;
				reg = <0x90000 0x400>;
				clocks = <&rcc CK_BUS_GPIOJ>;
				st,bank-name = "GPIOJ";
				status = "disabled";
			};

			gpiok: gpio@442e0000 {
				gpio-controller;
				#gpio-cells = <2>;
				interrupt-controller;
				#interrupt-cells = <2>;
				#access-controller-cells = <1>;
				reg = <0xa0000 0x400>;
				clocks = <&rcc CK_BUS_GPIOK>;
				st,bank-name = "GPIOK";
				status = "disabled";
			};
		};

		tamp: tamp@46010000 {
			compatible = "st,stm32mp25-tamp";
			reg = <0x46010000 0x400>;
			clocks = <&rcc CK_BUS_RTC>;
			interrupts = <GIC_SPI 14 IRQ_TYPE_LEVEL_HIGH>;
			#address-cells = <1>;
			#size-cells = <1>;
			ranges;
			st,backup-zones = <24 24 24 24 12 12 8>;
		};

		pinctrl_z: pinctrl-z@46200000 {
			#address-cells = <1>;
			#size-cells = <1>;
			compatible = "st,stm32mp257-z-pinctrl";
			ranges = <0 0x46200000 0x400>;
			pins-are-numbered;

			gpioz: gpio@46200000 {
				gpio-controller;
				#gpio-cells = <2>;
				interrupt-controller;
				#interrupt-cells = <2>;
				#access-controller-cells = <1>;
				reg = <0 0x400>;
				clocks = <&rcc CK_BUS_GPIOZ>;
				st,bank-name = "GPIOZ";
				st,bank-ioport = <11>;
				status = "disabled";
			};
		};

		hsem: hwspinlock@46240000 {
			compatible = "st,stm32mp25-hsem";
			reg = <0x46240000 0x400>;
			interrupts = <GIC_SPI 200 IRQ_TYPE_LEVEL_HIGH>;
			clocks = <&rcc CK_BUS_HSEM>;
			status = "disabled";
		};

		ipcc2: mailbox@46250000 {
			compatible = "st,stm32mp25-ipcc";
			reg = <0x46250000 0x400>;
			clocks = <&rcc CK_BUS_IPCC2>;
			status = "disabled";
		};

		fmc: memory-controller@48200000 {
			#address-cells = <2>;
			#size-cells = <1>;
			compatible = "st,stm32mp25-fmc2-ebi";
			reg = <0x48200000 0x400>;
			clocks = <&rcc CK_KER_FMC>;
			resets = <&rcc FMC_R>;
			status = "disabled";

			ranges = <0 0 0x60000000 0x04000000>, /* EBI CS 1 */
				 <1 0 0x64000000 0x04000000>, /* EBI CS 2 */
				 <2 0 0x68000000 0x04000000>, /* EBI CS 3 */
				 <3 0 0x6c000000 0x04000000>, /* EBI CS 4 */
				 <4 0 0x80000000 0x10000000>; /* NAND */
		};
	};
};
